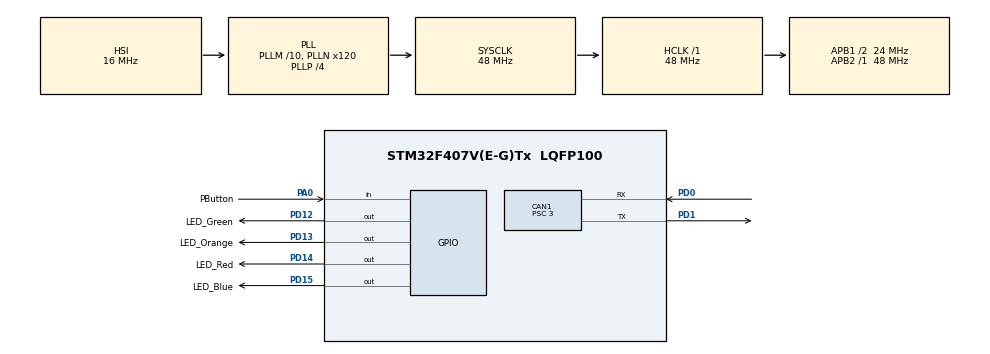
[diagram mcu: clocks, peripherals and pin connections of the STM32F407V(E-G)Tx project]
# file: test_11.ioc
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CAN1.BS1=CAN_BS1_13TQ
CAN1.BS2=CAN_BS2_2TQ
CAN1.CalculateTimeQuantum=125.0
CAN1.Prescaler=3
Mcu.Family=STM32F4
Mcu.Name=STM32F407V(E-G)Tx
Mcu.Package=LQFP100
NVIC.CAN1_RX0_IRQn=true\:0\:0\:false\:false\:true\:true
NVIC.CAN1_TX_IRQn=true\:0\:0\:false\:false\:true\:true
NVIC.PriorityGroup=NVIC_PRIORITYGROUP_0
PA0-WKUP.GPIO_Label=PButton
PA0-WKUP.Signal=GPIO_Input
PD0.Mode=Master
PD0.Signal=CAN1_RX
PD1.Mode=Master
PD1.Signal=CAN1_TX
PD12.GPIO_Label=LED_Green
PD12.Signal=GPIO_Output
PD13.GPIO_Label=LED_Orange
PD13.Signal=GPIO_Output
PD14.GPIO_Label=LED_Red
PD14.Signal=GPIO_Output
PD15.GPIO_Label=LED_Blue
PD15.Signal=GPIO_Output
ProjectManager.HeapSize=0x200
ProjectManager.StackSize=0x400
ProjectManager.TargetToolchain=SW4STM32
RCC.48MHZClocksFreq_Value=27428571.42857143
RCC.AHBFreq_Value=48000000
RCC.APB1CLKDivider=RCC_HCLK_DIV2
RCC.APB1Freq_Value=24000000
RCC.APB1TimFreq_Value=48000000
RCC.APB2Freq_Value=48000000
RCC.APB2TimFreq_Value=48000000
RCC.CortexFreq_Value=48000000
RCC.HCLKFreq_Value=48000000
RCC.HSE_VALUE=8000000
RCC.HSI_VALUE=16000000
RCC.LSE_VALUE=32768
RCC.PLLM=10
RCC.PLLN=120
RCC.PLLP=RCC_PLLP_DIV4
RCC.PLLQ=7
RCC.SYSCLKFreq_VALUE=48000000
RCC.SYSCLKSource=RCC_SYSCLKSOURCE_PLLCLK
RCC.VCOOutputFreq_Value=192000000
board=STM32F4DISCOVERY

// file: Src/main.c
/**
  ******************************************************************************
  * @file           : main.c
  * @brief          : Main program body
  ******************************************************************************
  ** This notice applies to any and all portions of this file
  * that are not between comment pairs USER CODE BEGIN and
  * USER CODE END. Other portions of this file, whether
  * inserted by the user or by software development tools
  * are owned by their respective copyright owners.
  *
  * COPYRIGHT(c) 2018 STMicroelectronics
  *
  * Redistribution and use in source and binary forms, with or without modification,
  * are permitted provided that the following conditions are met:
  *   1. Redistributions of source code must retain the above copyright notice,
  *      this list of conditions and the following disclaimer.
  *   2. Redistributions in binary form must reproduce the above copyright notice,
  *      this list of conditions and the following disclaimer in the documentation
  *      and/or other materials provided with the distribution.
  *   3. Neither the name of STMicroelectronics nor the names of its contributors
  *      may be used to endorse or promote products derived from this software
  *      without specific prior written permission.
  *
  * THIS SOFTWARE IS PROVIDED BY THE COPYRIGHT HOLDERS AND CONTRIBUTORS "AS IS"
  * AND ANY EXPRESS OR IMPLIED WARRANTIES, INCLUDING, BUT NOT LIMITED TO, THE
  * IMPLIED WARRANTIES OF MERCHANTABILITY AND FITNESS FOR A PARTICULAR PURPOSE ARE
  * DISCLAIMED. IN NO EVENT SHALL THE COPYRIGHT HOLDER OR CONTRIBUTORS BE LIABLE
  * FOR ANY DIRECT, INDIRECT, INCIDENTAL, SPECIAL, EXEMPLARY, OR CONSEQUENTIAL
  * DAMAGES (INCLUDING, BUT NOT LIMITED TO, PROCUREMENT OF SUBSTITUTE GOODS OR
  * SERVICES; LOSS OF USE, DATA, OR PROFITS; OR BUSINESS INTERRUPTION) HOWEVER
  * CAUSED AND ON ANY THEORY OF LIABILITY, WHETHER IN CONTRACT, STRICT LIABILITY,
  * OR TORT (INCLUDING NEGLIGENCE OR OTHERWISE) ARISING IN ANY WAY OUT OF THE USE
  * OF THIS SOFTWARE, EVEN IF ADVISED OF THE POSSIBILITY OF SUCH DAMAGE.
  *
  ******************************************************************************
  */
#include "main.h"
#include "stm32f4xx_hal.h"
#include "can.h"
#include "gpio.h"

/* USER CODE BEGIN PV */
/* Private variables ---------------------------------------------------------*/

/* USER CODE END PV */

void SystemClock_Config(void);

/* USER CODE BEGIN PFP */
/* Private function prototypes -----------------------------------------------*/

/* USER CODE END PFP */

int main(void)
{

  /* MCU Configuration----------------------------------------------------------*/

  /* Reset of all peripherals, Initializes the Flash interface and the Systick. */
  HAL_Init();

  /* Configure the system clock */
  SystemClock_Config();

  /* Initialize all configured peripherals */
  MX_GPIO_Init();
  MX_CAN1_Init();
  /* USER CODE BEGIN 2 */
  JDO_CanInit();
  /* USER CODE END 2 */

  /* Infinite loop */
  /* USER CODE BEGIN WHILE */
  while (1)
  {
	  if(HAL_GPIO_ReadPin(PButton_GPIO_Port,PButton_Pin))
	  {
		  HAL_GPIO_WritePin(LED_Orange_GPIO_Port,LED_Orange_Pin,1);
		  JDO_SendCan();
		  HAL_GPIO_WritePin(LED_Orange_GPIO_Port,LED_Orange_Pin,0);
	  }
  /* USER CODE END WHILE */

  }

}

void SystemClock_Config(void)
{

  RCC_OscInitTypeDef RCC_OscInitStruct;
  RCC_ClkInitTypeDef RCC_ClkInitStruct;

    /**Configure the main internal regulator output voltage
    */
  __HAL_RCC_PWR_CLK_ENABLE();

  __HAL_PWR_VOLTAGESCALING_CONFIG(PWR_REGULATOR_VOLTAGE_SCALE1);

    /**Initializes the CPU, AHB and APB busses clocks
    */
  RCC_OscInitStruct.OscillatorType = RCC_OSCILLATORTYPE_HSI;
  RCC_OscInitStruct.HSIState = RCC_HSI_ON;
  RCC_OscInitStruct.HSICalibrationValue = 16;
  RCC_OscInitStruct.PLL.PLLState = RCC_PLL_ON;
  RCC_OscInitStruct.PLL.PLLSource = RCC_PLLSOURCE_HSI;
  RCC_OscInitStruct.PLL.PLLM = 10;
  RCC_OscInitStruct.PLL.PLLN = 120;
  RCC_OscInitStruct.PLL.PLLP = RCC_PLLP_DIV4;
  RCC_OscInitStruct.PLL.PLLQ = 7;
  if (HAL_RCC_OscConfig(&RCC_OscInitStruct) != HAL_OK)
  {
    _Error_Handler(__FILE__, __LINE__);
  }

    /**Initializes the CPU, AHB and APB busses clocks
    */
  RCC_ClkInitStruct.ClockType = RCC_CLOCKTYPE_HCLK|RCC_CLOCKTYPE_SYSCLK
                              |RCC_CLOCKTYPE_PCLK1|RCC_CLOCKTYPE_PCLK2;
  RCC_ClkInitStruct.SYSCLKSource = RCC_SYSCLKSOURCE_PLLCLK;
  RCC_ClkInitStruct.AHBCLKDivider = RCC_SYSCLK_DIV1;
  RCC_ClkInitStruct.APB1CLKDivider = RCC_HCLK_DIV2;
  RCC_ClkInitStruct.APB2CLKDivider = RCC_HCLK_DIV1;

  if (HAL_RCC_ClockConfig(&RCC_ClkInitStruct, FLASH_LATENCY_1) != HAL_OK)
  {
    _Error_Handler(__FILE__, __LINE__);
  }

    /**Configure the Systick interrupt time
    */
  HAL_SYSTICK_Config(HAL_RCC_GetHCLKFreq()/1000);

    /**Configure the Systick
    */
  HAL_SYSTICK_CLKSourceConfig(SYSTICK_CLKSOURCE_HCLK);

  /* SysTick_IRQn interrupt configuration */
  HAL_NVIC_SetPriority(SysTick_IRQn, 0, 0);
}

void _Error_Handler(char *file, int line)
{
  while(1)
  {
  }
}

/************************ (C) COPYRIGHT STMicroelectronics *****END OF FILE****/
